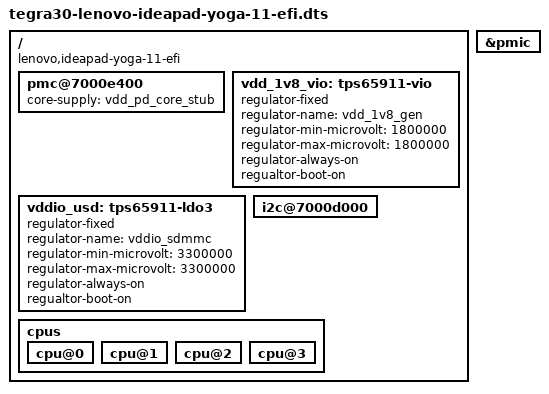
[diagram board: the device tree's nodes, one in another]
// SPDX-License-Identifier: GPL-2.0-only

#include "tegra30-lenovo-ideapad-yoga-11.dts"

/*
 * Temporary Lenovo Ideapad Yoga 11 device-tree for EFI booting.
 * Replacing PMIC with fixed regulators.
 */

/ {
	compatible = "lenovo,ideapad-yoga-11-efi", "lenovo,ideapad-yoga-11", "nvidia,tegra30";

	/* L2 cache does not work yet */
	/delete-node/ cache-controller@50043000;

	pmc@7000e400 {
		/* CPU Idle does not work yet, disabling LP2 */
		/delete-property/ nvidia,suspend-mode;

		/* Core regulator cannot work with UEFI, use fallback stub */
		core-supply = <&vdd_pd_core_stub>;
	};

	vdd_1v8_vio: tps65911-vio {
		compatible = "regulator-fixed";
		regulator-name = "vdd_1v8_gen";
		regulator-min-microvolt = <1800000>;
		regulator-max-microvolt = <1800000>;
		regulator-always-on;
		regualtor-boot-on;
	};

	vddio_usd: tps65911-ldo3 {
		compatible = "regulator-fixed";
		regulator-name = "vddio_sdmmc";
		regulator-min-microvolt = <3300000>;
		regulator-max-microvolt = <3300000>;
		regulator-always-on;
		regualtor-boot-on;
	};

	/* Core regulator cannot work with UEFI, delete it */
	i2c@7000d000 {
		/delete-node/ core-regulator@60;
	};

	/* DVFS cannot work with UEFI, delete it */
	cpus {
		cpu@0 {
			/delete-property/ cpu-supply;
			/delete-property/ operating-points-v2;
		};

		cpu@1 {
			/delete-property/ cpu-supply;
			/delete-property/ operating-points-v2;
		};

		cpu@2 {
			/delete-property/ cpu-supply;
			/delete-property/ operating-points-v2;
		};

		cpu@3 {
			/delete-property/ cpu-supply;
			/delete-property/ operating-points-v2;
		};
	};
};

&pmic {
	/delete-node/ regulators;
};
